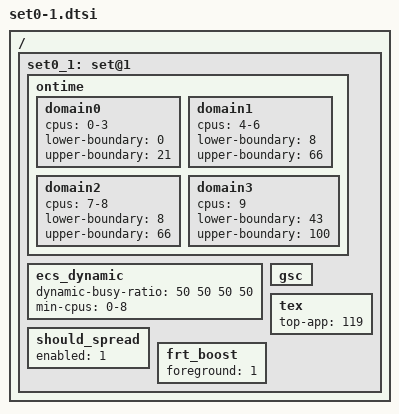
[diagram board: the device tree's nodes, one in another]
/ {
	/* normal mode - touch boost */
	set0_1: set@1 {
		/* Ontime Migration */
		ontime {
			domain0 {
				cpus = "0-3";
				lower-boundary = <0>;
				upper-boundary = <21>;
			};
			domain1 {
				cpus = "4-6";
				lower-boundary = <8>;
				upper-boundary = <66>;
			};
			domain2 {
				cpus = "7-8";
				lower-boundary = <8>;
				upper-boundary = <66>;
			};
			domain3 {
				cpus = "9";
				lower-boundary = <43>;
				upper-boundary = <100>;
			};
		};

		ecs_dynamic {
			dynamic-busy-ratio = <50 50 50 50>;
			min-cpus = "0-8";
		};

		gsc { };

		tex {
			top-app = <119>;
		};

		should_spread {
			enabled = <1>;
		};

		frt_boost {
			foreground = <1>;
		};
	};
};
